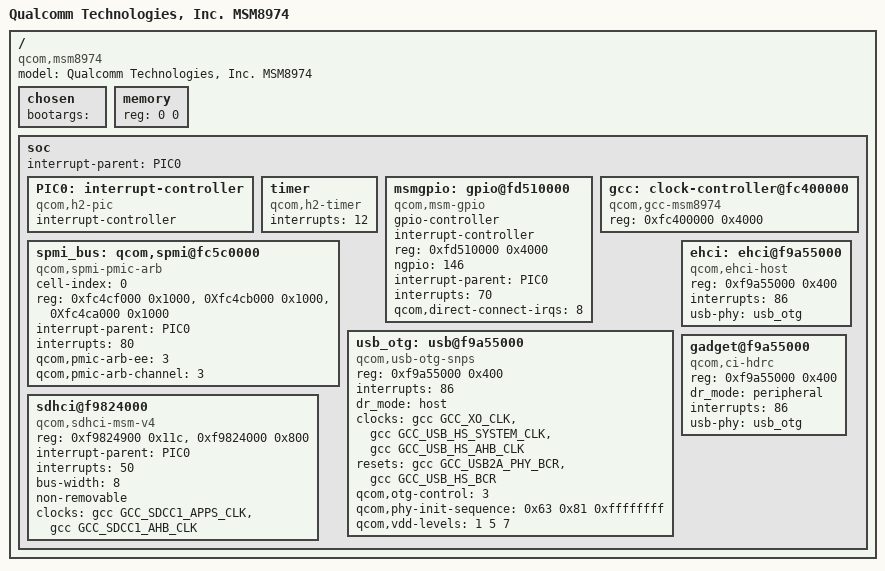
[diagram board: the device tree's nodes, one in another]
/* Copyright (c) 2013-2015, The Linux Foundation. All rights reserved.
 *
 * This program is free software; you can redistribute it and/or modify
 * it under the terms of the GNU General Public License version 2 and
 * only version 2 as published by the Free Software Foundation.
 *
 * This program is distributed in the hope that it will be useful,
 * but WITHOUT ANY WARRANTY; without even the implied warranty of
 * MERCHANTABILITY or FITNESS FOR A PARTICULAR PURPOSE.  See the
 * GNU General Public License for more details.
 */

/dts-v1/;

#include <dt-bindings/clock/qcom,gcc-msm8974.h>
#include <dt-bindings/reset/qcom,gcc-msm8974.h>

/*  Bare minimum  */
/ {
	#address-cells = <1>;
	#size-cells = <1>;
	chosen { };
	memory { device_type = "memory"; reg = <0 0>; };
};


/ {
	chosen {
		bootargs = "";
	};
};


/ {
	model = "Qualcomm Technologies, Inc. MSM8974";
	compatible = "qcom,msm8974";

	soc: soc {
		#address-cells = <1>;
		#size-cells = <1>;
		ranges;
		interrupt-parent = <&PIC0>;

		PIC0: interrupt-controller {
			compatible = "qcom,h2-pic";
			interrupt-controller;
			#interrupt-cells = <1>;
		};

		timer {
			compatible="qcom,h2-timer";
			interrupts = <12>;
		};

		msmgpio: gpio@fd510000 {
			compatible = "qcom,msm-gpio";
			gpio-controller;
			#gpio-cells = <2>;
			interrupt-controller;
			#interrupt-cells = <2>;
			reg = <0xfd510000 0x4000>;
			ngpio = <146>;
			interrupt-parent = <&PIC0>;
			interrupts = <70>;
			qcom,direct-connect-irqs = <8>;
		};

		spmi_bus: qcom,spmi@fc5c0000 {
			cell-index = <0>;
			compatible = "qcom,spmi-pmic-arb";
			reg-names = "core", "intr", "cnfg";
			reg = <0xfc4cf000 0x1000>,
			      <0Xfc4cb000 0x1000>,
			      <0Xfc4ca000 0x1000>;
			interrupt-parent = <&PIC0>;
			interrupts = <80>;
			qcom,pmic-arb-ee = <3>;
			qcom,pmic-arb-channel = <3>;
		};

		gcc: clock-controller@fc400000 {
			compatible = "qcom,gcc-msm8974", "qcom,gcc";
			#clock-cells = <1>;
			#reset-cells = <1>;
			reg = <0xfc400000 0x4000>;
		};

		usb_otg: usb@f9a55000 {
			compatible = "qcom,usb-otg-snps";
			reg = <0xf9a55000 0x400>;
			interrupts = <86>;  /*  54 + 32  */
			dr_mode = "host";

			clocks = <&gcc GCC_XO_CLK>,
				 <&gcc GCC_USB_HS_SYSTEM_CLK>,
				 <&gcc GCC_USB_HS_AHB_CLK>;
			clock-names = "phy", "core", "iface";

			/*  vddcx-supply = <&pm8841_s2_corner>;  not supported yet */
			/*  v1p8-supply = <&pm8941_l6>;  not supported yet  */
			/*  v3p3-supply = <&pm8941_l24>;  not supoprted yet  */

			resets = <&gcc GCC_USB2A_PHY_BCR>,
				 <&gcc GCC_USB_HS_BCR>;
			reset-names = "phy", "link";

			qcom,otg-control = <3>;
			qcom,phy-init-sequence = <0x63 0x81 0xffffffff>;
			qcom,vdd-levels = <1 5 7>;
		};

		ehci: ehci@f9a55000 {
			compatible = "qcom,ehci-host";
			reg = <0xf9a55000 0x400>;
			interrupts = <86>;  /*  54 + 32  */
			usb-phy = <&usb_otg>;
			status="ok";
		};

		gadget@f9a55000 {
			compatible = "qcom,ci-hdrc";
			reg = <0xf9a55000 0x400>;
			dr_mode = "peripheral";
			interrupts = <86>;  /*  54 + 32  */
			usb-phy = <&usb_otg>;
		};

	};
};


&soc {
	sdhci@f9824000 {
		compatible = "qcom,sdhci-msm-v4";
		reg = <0xf9824900 0x11c>, <0xf9824000 0x800>;
		reg-names = "hc_mem", "core_mem";
		interrupt-parent = <&PIC0>;
		interrupts = <50>;

		bus-width = <8>;
		non-removable;

		clocks = <&gcc GCC_SDCC1_APPS_CLK>, <&gcc GCC_SDCC1_AHB_CLK>;
		clock-names = "core", "iface";
	};
};
